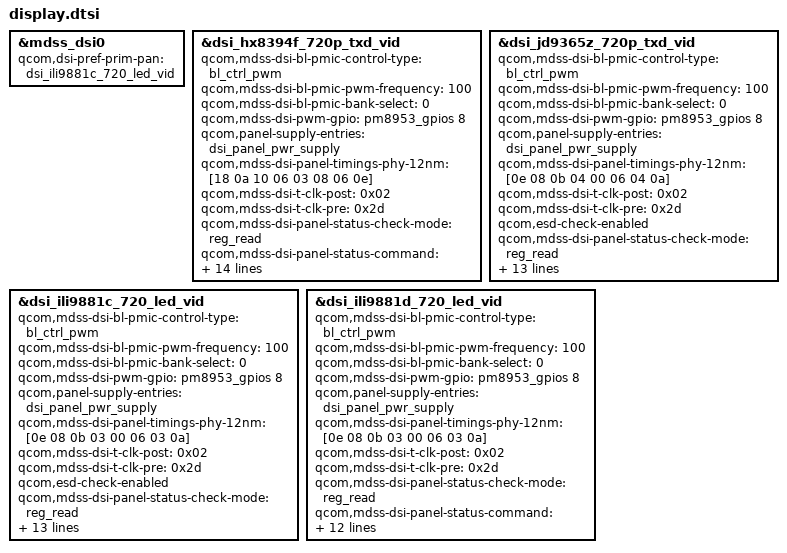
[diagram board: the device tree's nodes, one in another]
&mdss_dsi0 {
	qcom,dsi-pref-prim-pan = <&dsi_ili9881c_720_led_vid>;
};

&dsi_hx8394f_720p_txd_vid {
	qcom,mdss-dsi-bl-pmic-control-type = "bl_ctrl_pwm";
	qcom,mdss-dsi-bl-pmic-pwm-frequency = <100>;
	qcom,mdss-dsi-bl-pmic-bank-select = <0>;
	qcom,mdss-dsi-pwm-gpio = <&pm8953_gpios 8 0>;
	qcom,panel-supply-entries = <&dsi_panel_pwr_supply>;
	/delete-property/ qcom,mdss-dsi-panel-timings;
	qcom,mdss-dsi-panel-timings-phy-12nm = [18 0a 10 06 03 08 06 0e];
	qcom,mdss-dsi-t-clk-post = <0x02>;
	qcom,mdss-dsi-t-clk-pre = <0x2d>;
	qcom,mdss-dsi-panel-status-check-mode = "reg_read";
	qcom,mdss-dsi-panel-status-command = [06 01 00 01 00 00 01 0a];
	qcom,mdss-dsi-panel-status-command-state = "dsi_lp_mode";
	qcom,mdss-dsi-panel-status-value = <0x9d 0x9d 0x9d 0x9d>;
	qcom,mdss-dsi-panel-on-check-value = <0x9d 0x9d 0x9d 0x9d>;
	qcom,mdss-dsi-panel-status-read-length = <4>;
	qcom,mdss-dsi-panel-max-error-count = <3>;
	qcom,mdss-dsi-min-refresh-rate = <48>;
	qcom,mdss-dsi-max-refresh-rate = <60>;
	qcom,mdss-dsi-pan-enable-dynamic-fps;
	qcom,mdss-dsi-pan-fps-update =
		"dfps_immediate_porch_mode_vfp";
};

&dsi_jd9365z_720p_txd_vid {
        qcom,mdss-dsi-bl-pmic-control-type = "bl_ctrl_pwm";
        qcom,mdss-dsi-bl-pmic-pwm-frequency = <100>;
        qcom,mdss-dsi-bl-pmic-bank-select = <0>;
        qcom,mdss-dsi-pwm-gpio = <&pm8953_gpios 8 0>;
        qcom,panel-supply-entries = <&dsi_panel_pwr_supply>;
        /delete-property/ qcom,mdss-dsi-panel-timings;
        qcom,mdss-dsi-panel-timings-phy-12nm = [0e 08 0b 04 00 06 04 0a];
        qcom,mdss-dsi-t-clk-post = <0x02>;
        qcom,mdss-dsi-t-clk-pre = <0x2d>;
	qcom,esd-check-enabled;
        qcom,mdss-dsi-panel-status-check-mode = "reg_read";
        qcom,mdss-dsi-panel-status-command = [06 01 00 01 00 00 01 0a];
        qcom,mdss-dsi-panel-status-command-state = "dsi_lp_mode";
        qcom,mdss-dsi-panel-status-value = <0x1c>;
        qcom,mdss-dsi-panel-on-check-value = <0x1c>;
        qcom,mdss-dsi-panel-status-read-length = <1>;
        qcom,mdss-dsi-panel-max-error-count = <3>;
        qcom,mdss-dsi-min-refresh-rate = <48>;
        qcom,mdss-dsi-max-refresh-rate = <60>;
        qcom,mdss-dsi-pan-enable-dynamic-fps;
        qcom,mdss-dsi-pan-fps-update =
                "dfps_immediate_porch_mode_vfp";
};

&dsi_ili9881c_720_led_vid {
	qcom,mdss-dsi-bl-pmic-control-type = "bl_ctrl_pwm";
	qcom,mdss-dsi-bl-pmic-pwm-frequency = <100>;
	qcom,mdss-dsi-bl-pmic-bank-select = <0>;
	qcom,mdss-dsi-pwm-gpio = <&pm8953_gpios 8 0>;
	qcom,panel-supply-entries = <&dsi_panel_pwr_supply>;
	/delete-property/ qcom,mdss-dsi-panel-timings;
	qcom,mdss-dsi-panel-timings-phy-12nm = [0e 08 0b 03 00 06 03 0a];
	qcom,mdss-dsi-t-clk-post = <0x02>;
	qcom,mdss-dsi-t-clk-pre = <0x2d>;
	qcom,esd-check-enabled;
	qcom,mdss-dsi-panel-status-check-mode = "reg_read";
	qcom,mdss-dsi-panel-status-command = [06 01 00 01 00 00 01 0a];
	qcom,mdss-dsi-panel-status-command-state = "dsi_lp_mode";
	qcom,mdss-dsi-panel-status-value = <0x9c>;
	qcom,mdss-dsi-panel-on-check-value = <0x9c>;
	qcom,mdss-dsi-panel-status-read-length = <1>;
	qcom,mdss-dsi-panel-max-error-count = <3>;
	qcom,mdss-dsi-min-refresh-rate = <48>;
	qcom,mdss-dsi-max-refresh-rate = <60>;
	qcom,mdss-dsi-pan-enable-dynamic-fps;
	qcom,mdss-dsi-pan-fps-update =
		"dfps_immediate_porch_mode_vfp";
};

&dsi_ili9881d_720_led_vid {
	qcom,mdss-dsi-bl-pmic-control-type = "bl_ctrl_pwm";
	qcom,mdss-dsi-bl-pmic-pwm-frequency = <100>;
	qcom,mdss-dsi-bl-pmic-bank-select = <0>;
	qcom,mdss-dsi-pwm-gpio = <&pm8953_gpios 8 0>;
	qcom,panel-supply-entries = <&dsi_panel_pwr_supply>;
	/delete-property/ qcom,mdss-dsi-panel-timings;
	qcom,mdss-dsi-panel-timings-phy-12nm = [0e 08 0b 03 00 06 03 0a];
	qcom,mdss-dsi-t-clk-post = <0x02>;
	qcom,mdss-dsi-t-clk-pre = <0x2d>;
	qcom,mdss-dsi-panel-status-check-mode = "reg_read";
	qcom,mdss-dsi-panel-status-command = [06 01 00 01 00 00 01 0a];
	qcom,mdss-dsi-panel-status-command-state = "dsi_lp_mode";
	qcom,mdss-dsi-panel-status-value = <0x9d>;
	qcom,mdss-dsi-panel-on-check-value = <0x9d>;
	qcom,mdss-dsi-panel-status-read-length = <1>;
	qcom,mdss-dsi-panel-max-error-count = <3>;
	qcom,mdss-dsi-min-refresh-rate = <48>;
	qcom,mdss-dsi-max-refresh-rate = <60>;
	qcom,mdss-dsi-pan-enable-dynamic-fps;
	qcom,mdss-dsi-pan-fps-update =
		"dfps_immediate_porch_mode_vfp";
};
